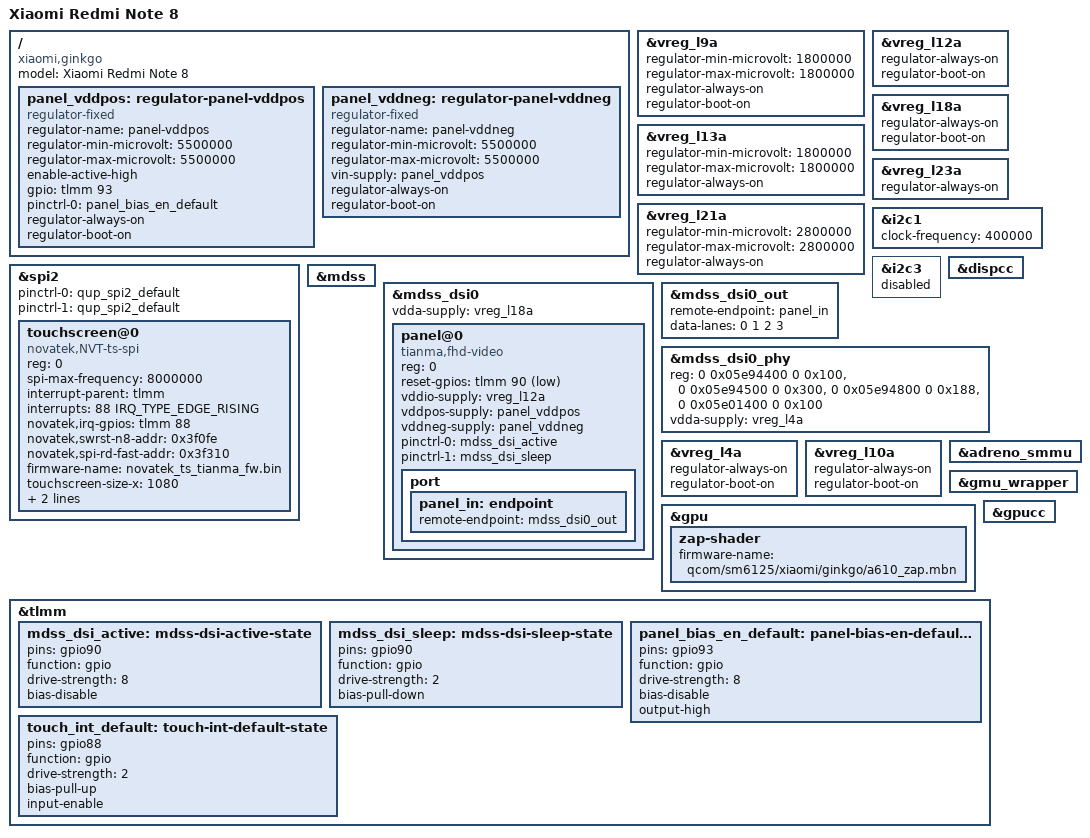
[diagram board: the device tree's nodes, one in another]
// SPDX-License-Identifier: BSD-3-Clause
/*
 * Copyright (c) 2025, Gabriel Gonzales <semfault@disroot.org>
 */
/dts-v1/;

#include <dt-bindings/gpio/gpio.h>
#include <dt-bindings/interrupt-controller/irq.h>
#include "sm6125-xiaomi-ginkgo-common.dtsi"

/ {
	model = "Xiaomi Redmi Note 8";
	compatible = "xiaomi,ginkgo", "qcom,sm6125";

	/*
	 * The NT36672A panel requires +5.5V and -5.5V bias rails.
	 * On ginkgo these are provided by an LCD bias chip enabled via GPIO 93.
	 * vddneg shares the same enable (both rails from one bias IC).
	 */
	panel_vddpos: regulator-panel-vddpos {
		compatible = "regulator-fixed";
		regulator-name = "panel-vddpos";
		regulator-min-microvolt = <5500000>;
		regulator-max-microvolt = <5500000>;
		enable-active-high;
		gpio = <&tlmm 93 GPIO_ACTIVE_HIGH>;
		pinctrl-names = "default";
		pinctrl-0 = <&panel_bias_en_default>;
		regulator-always-on;
		regulator-boot-on;
	};

	panel_vddneg: regulator-panel-vddneg {
		compatible = "regulator-fixed";
		regulator-name = "panel-vddneg";
		regulator-min-microvolt = <5500000>;
		regulator-max-microvolt = <5500000>;
		vin-supply = <&panel_vddpos>;
		regulator-always-on;
		regulator-boot-on;
	};

};

&vreg_l9a {
	regulator-min-microvolt = <1800000>;
	regulator-max-microvolt = <1800000>;
	regulator-always-on;
	regulator-boot-on;
};

&vreg_l12a {
	regulator-always-on;
	regulator-boot-on;
};

&vreg_l18a {
	regulator-always-on;
	regulator-boot-on;
};

&vreg_l13a {
	regulator-min-microvolt = <1800000>;
	regulator-max-microvolt = <1800000>;
	regulator-always-on;
};

&vreg_l21a {
	regulator-min-microvolt = <2800000>;
	regulator-max-microvolt = <2800000>;
	regulator-always-on;
};

&vreg_l23a {
	regulator-always-on;
};

&i2c1 {
	clock-frequency = <400000>;
	status = "okay";
};

&spi2 {
	status = "okay";
	pinctrl-0 = <&qup_spi2_default>;
	pinctrl-1 = <&qup_spi2_default>;
	pinctrl-names = "default", "sleep";
	/delete-property/ dmas;
	/delete-property/ dma-names;

	touchscreen@0 {
		compatible = "novatek,NVT-ts-spi";
		reg = <0>;
		spi-max-frequency = <8000000>;

		interrupt-parent = <&tlmm>;
		interrupts = <88 IRQ_TYPE_EDGE_RISING>;

		novatek,irq-gpios = <&tlmm 88 IRQ_TYPE_EDGE_RISING>;
		novatek,swrst-n8-addr = <0x3f0fe>;
		novatek,spi-rd-fast-addr = <0x3f310>;
		firmware-name = "novatek_ts_tianma_fw.bin";
		touchscreen-size-x = <1080>;
		touchscreen-size-y = <2340>;

		pinctrl-names = "default";
		pinctrl-0 = <&touch_int_default>;
	};
};

&i2c3 {
	status = "disabled";
};

&dispcc {
	status = "okay";
};

&mdss {
	status = "okay";
};

&mdss_dsi0 {
	vdda-supply = <&vreg_l18a>;
	status = "okay";

	panel@0 {
		compatible = "tianma,fhd-video";
		reg = <0>;

		reset-gpios = <&tlmm 90 GPIO_ACTIVE_LOW>;
		vddio-supply = <&vreg_l12a>;
		vddpos-supply = <&panel_vddpos>;
		vddneg-supply = <&panel_vddneg>;

		pinctrl-names = "default", "sleep";
		pinctrl-0 = <&mdss_dsi_active>;
		pinctrl-1 = <&mdss_dsi_sleep>;

		port {
			panel_in: endpoint {
				remote-endpoint = <&mdss_dsi0_out>;
			};
		};
	};
};

&mdss_dsi0_out {
	remote-endpoint = <&panel_in>;
	data-lanes = <0 1 2 3>;
};

&mdss_dsi0_phy {
	reg = <0 0x05e94400 0 0x100>,
	      <0 0x05e94500 0 0x300>,
	      <0 0x05e94800 0 0x188>,
	      <0 0x05e01400 0 0x100>;
	reg-names = "dsi_phy", "dsi_phy_lane", "dsi_pll", "dsi_phy_clamp";
	/* Stock DTBO: vdda-phy = pm6125_l4 (0.9V), vdda-pll = pm6125_l10 (1.8V) */
	vdda-supply = <&vreg_l4a>;
	status = "okay";
};

&vreg_l4a {
	regulator-always-on;
	regulator-boot-on;
};

&vreg_l10a {
	regulator-always-on;
	regulator-boot-on;
};

&adreno_smmu {
	status = "okay";
};

&gmu_wrapper {
	status = "okay";
};

&gpu {
	status = "okay";

	zap-shader {
		firmware-name = "qcom/sm6125/xiaomi/ginkgo/a610_zap.mbn";
	};
};

&gpucc {
	status = "okay";
};

&tlmm {
	mdss_dsi_active: mdss-dsi-active-state {
		pins = "gpio90";
		function = "gpio";
		drive-strength = <8>;
		bias-disable;
	};

	mdss_dsi_sleep: mdss-dsi-sleep-state {
		pins = "gpio90";
		function = "gpio";
		drive-strength = <2>;
		bias-pull-down;
	};

	panel_bias_en_default: panel-bias-en-default-state {
		pins = "gpio93";
		function = "gpio";
		drive-strength = <8>;
		bias-disable;
		output-high;
	};

	touch_int_default: touch-int-default-state {
		pins = "gpio88";
		function = "gpio";
		drive-strength = <2>;
		bias-pull-up;
		input-enable;
	};
};
